# LPC5410x register map
File version: 0.4
CPU: CM4 r0p0, little endian, no MPU, no FPU, 0x3 interrupt priority bits, 0x0 interrupts
Registers are 32-bit, read-write, reset 0x0 unless marked. A register's access mark holds for its fields unless they carry their own. Offsets are from the block's base; [hi:lo] are bit positions; {n}, {i} and the like mark numbered series.

## ADVSYSCON — Advanced System configuration
Base 0x4002C000
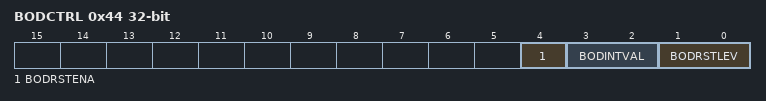
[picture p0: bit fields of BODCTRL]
0x44 BODCTRL — Brown-Out Detect control
  [4] BODRSTENA — BOD reset enable
    0=DISABLE_RESET_FUNCTI (Disable reset function.); 1=ENABLE_RESET_FUNCTIO (Enable reset function.)
  [3:2] BODINTVAL — BOD interrupt level
    0=LEVEL_0_2 (Level 0: 2.05 V); 1=LEVEL_1_2 (Level 1: 2.45 V); 2=LEVEL_2_2 (Level 2: 2.75 V); 3=LEVEL_3_3 (Level 3: 3.05 V)
  [1:0] BODRSTLEV — BOD reset level
    0=LEVEL_0_1 (Level 0: 1.5 V); 1=LEVEL_1_1 (Level 1: 1.85 V); 2=LEVEL_2_2 (Level 2: 2.0 V); 3=LEVEL_3_2 (Level 3: 2.3 V)

## WWDT — Windowed Watchdog Timer
Base 0x40038000
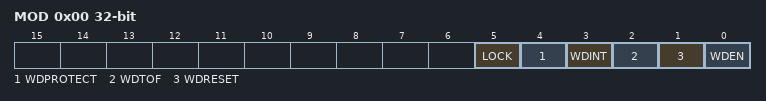
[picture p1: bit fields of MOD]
0x00 MOD — Watchdog mode register. This register contains the basic mode and status of the Watchdog Timer.
  [5] LOCK — Once this bit is set to one and a watchdog feed is performed, disabling or powering down the watchdog oscillator is prevented by hardware. This bit can be set once by software and is only cleared by any reset.
  [4] WDPROTECT — Watchdog update mode. This bit can be set once by software and is only cleared by a reset.
    0=FLEXIBLE (Flexible. The watchdog time-out value (TC) can be changed at any time.); 1=THRESHOLD (Threshold. The watchdog time-out value (TC) can be changed only after the counter is below the value of WDWARNINT and WDWINDOW.)
  [3] WDINT — Warning interrupt flag. Set when the timer reaches the value in WDWARNINT. Cleared by software.
  [2] WDTOF — Watchdog time-out flag. Set when the watchdog timer times out, by a feed error, or by events associated with WDPROTECT. Cleared by software. Causes a chip reset if WDRESET = 1.
  [1] WDRESET — Watchdog reset enable bit. Once this bit has been written with a 1 it cannot be re-written with a 0.
    0=INTERRUPT (Interrupt. A watchdog time-out will not cause a chip reset.); 1=RESET (Reset. A watchdog time-out will cause a chip reset.)
  [0] WDEN — Watchdog enable bit. Once this bit is set to one and a watchdog feed is performed, the watchdog timer will run permanently.
    0=STOP (Stop. The watchdog timer is stopped.); 1=RUN (Run. The watchdog timer is running.)
0x04 TC reset 0xFF — Watchdog timer constant register. This 24-bit register determines the time-out value.
  [23:0] COUNT — Watchdog time-out value.
0x08 FEED wo reset not defined — Watchdog feed sequence register. Writing 0xAA followed by 0x55 to this register reloads the Watchdog timer with the value contained in WDTC.
  [7:0] FEED — Feed value should be 0xAA followed by 0x55.
0x0C TV ro reset 0xFF — Watchdog timer value register. This 24-bit register reads out the current value of the Watchdog timer.
  [23:0] COUNT — Counter timer value.
0x14 WARNINT — Watchdog Warning Interrupt compare value.
  [9:0] WARNINT — Watchdog warning interrupt compare value.
0x18 WINDOW reset 0xFFFFFF — Watchdog Window compare value.
  [23:0] WINDOW — Watchdog window value.

## INPUTMUX — Input multiplexing
Base 0x40050000
{0xC0+4i} PINTSEL{i} (i=0..7) — Pin interrupt select register 0
  [7:0] INTPIN — Pin number select for pin interrupt or pattern match engine input. (PIO0_0 to PIO1_31 correspond to numbers 0 to 63).
{0xE0+4i} DMA_ITRIG_INMUX{i} reset 0x1F (i=0..21) — Trigger select register for DMA channel 0
  [4:0] INP — Trigger input number (decimal value) for DMA channel n (n = 0 to 21). 0 = ADC0 Sequence A interrupt 1 = ADC0 Sequence B interrupt 2 = SCT0 DMA request 0 3 = SCT0 DMA request 1 4 = Timer 0 Match 0 5 = Timer 0 Match 1 6 = Timer 1 Match 0 7 = Timer 2 Match 0 8 = Timer 2 Match 1 9 = Timer 3 Match 0 10 = Timer 4 Match 0 11 = Timer 4 Match 1 12 = Pin interrupt 0 13 = Pin interrupt 1 14 = Pin interrupt 2 15 = Pin interrupt 3 16 = DMA output trigger mux 0 17 = DMA output trigger mux 1 18 = DMA output trigger mux 2 19 = DMA output trigger mux 3
{0x140+4i} DMA_OTRIG_INMUX{i} reset 0x1F (i=0..3) — DMA output trigger selection to become DMA trigger 16
  [4:0] INP — DMA trigger output number (decimal value) for DMA channel n (n = 0 to 19).
0x160 FREQMEAS_REF reset 0x1F — Clock selection for frequency measurement function reference clock
  [4:0] CLKIN — Clock source number (decimal value) for frequency measure function target clock: 0 = System oscillator (MAIN_OSC) 1 = IRC oscillator 2 = Watchdog oscillator 3 = 32 kHz RTC oscillator 4 = Main clock (see Section 4.5.21) 5 = PIO0_4 6 = PIO0_20 7 = PIO0_24 8 = PIO1_4
0x164 FREQMEAS_TARGET reset 0x1F — Clock selection for frequency measurement function target clock
  [4:0] CLKIN — Clock source number (decimal value) for frequency measure function target clock: 0 = System oscillator (MAIN_OSC) 1 = IRC oscillator 2 = Watchdog oscillator 3 = 32 kHz RTC oscillator 4 = Main clock (see Section 4.5.18) 5 = PIO0_4 6 = PIO0_20 7 = PIO0_24 8 = PIO1_4

## RIT — Repetitive Interrupt Timer
Base 0x40070000
0x00 COMPVAL reset 0xFFFFFFFF — Compare value LSB register. Holds the 32 LSBs of the compare value.
  [31:0] RICOMP — Compare register. Holds the 32 LSBs of the value which is compared to the counter.
0x04 MASK — Mask LSB register. This register holds the 32 LSB s of the mask value. A 1 written to any bit will force the compare to be true for the corresponding bit of the counter and compare register.
  [31:0] RIMASK — Mask register. This register holds the 32 LSBs of the mask value. A one written to any bit overrides the result of the comparison for the corresponding bit of the counter and compare register (causes the comparison of the register bits to be always true).
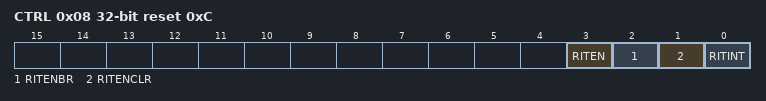
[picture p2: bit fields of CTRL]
0x08 CTRL reset 0xC — Control register.
  [3] RITEN — Timer enable.
    1=TIMER_ENABLED (Timer enabled. This can be overruled by a debug halt if enabled in bit 2.); 0=TIMER_DISABLED
  [2] RITENBR — Timer enable for debug
    1=HALT (The timer is halted when the processor is halted for debugging.); 0=DEBUG (Debug has no effect on the timer operation.)
  [1] RITENCLR — Timer enable clear
    1=CLEAR (The timer will be cleared to 0 whenever the counter value equals the masked compare value specified by the contents of COMPVAL/COMPVAL_H and MASK/MASK_H registers. This will occur on the same clock that sets the interrupt flag.); 0=NOCLEAR (The timer will not be cleared to 0.)
  [0] RITINT — Interrupt flag
    1=MATCH (This bit is set to 1 by hardware whenever the counter value equals the masked compare value specified by the contents of RICOMPVAL and RIMASK registers. Writing a 1 to this bit will clear it to 0. Writing a 0 has no effect.); 0=NOMTCH (The counter value does not equal the masked compare value.)
0x0C COUNTER — Counter LSB register. 32 LSBs of the counter.
  [31:0] RICOUNTER — 32 LSBs of the up counter. Counts continuously unless RITEN bit in CTRL register is cleared or debug mode is entered (if enabled by the RITNEBR bit in RICTRL). Can be loaded to any value in software.
0x10 COMPVAL_H reset 0xFFFF — Compare value MSB register. Holds the 16 MSBs of the compare value.
  [15:0] RICOMP — Compare value MSB register. Holds the 16 MSBs of the value which is compared to the counter.
0x14 MASK_H — Mask MSB register. This register holds the 16 MSBs of the mask value. A 1 written to any bit will force a compare on the corresponding bit of the counter and compare register.
  [15:0] RIMASK — Mask register. This register holds the 16 MSBs of the mask value. A one written to any bit overrides the result of the comparison for the corresponding bit of the counter and compare register (causes the comparison of the register bits to be always true).
0x1C COUNTER_H — Counter MSB register. 16 MSBs of the counter.
  [15:0] RICOUNTER — 16 LSBs of the up counter. Counts continuously unless RITEN bit in RICTRL register is cleared or debug mode is entered (if enabled by the RITNEBR bit in RICTRL). Can be loaded to any value in software.
